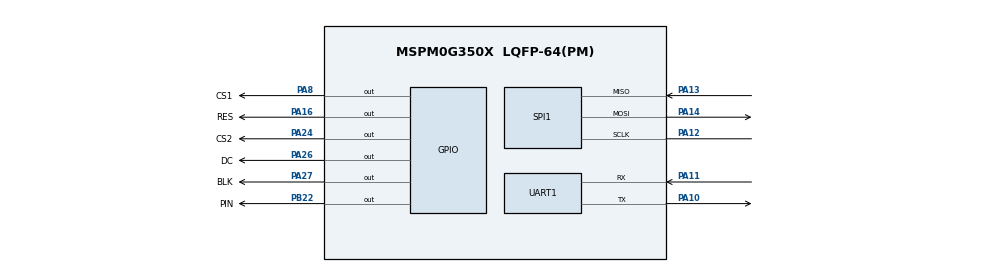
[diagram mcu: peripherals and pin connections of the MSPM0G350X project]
/**
 * @cliArgs --device "MSPM0G350X" --part "Default" --package "LQFP-64(PM)" --product "mspm0_sdk@2.02.00.05"
 * @versions {"tool":"1.21.0+3721"}
 */

/**
 * Import the modules used in this configuration.
 */
const GPIO   = scripting.addModule("/ti/driverlib/GPIO", {}, false);
const GPIO1  = GPIO.addInstance();
const GPIO2  = GPIO.addInstance();
const SPI    = scripting.addModule("/ti/driverlib/SPI", {}, false);
const SPI1   = SPI.addInstance();
const SYSCTL = scripting.addModule("/ti/driverlib/SYSCTL");
const UART   = scripting.addModule("/ti/driverlib/UART", {}, false);
const UART1  = UART.addInstance();

/**
 * Write custom configuration values to the imported modules.
 */
const divider9       = system.clockTree["UDIV"];
divider9.divideValue = 2;

const mux4       = system.clockTree["EXHFMUX"];
mux4.inputSelect = "EXHFMUX_XTAL";

const mux8       = system.clockTree["HSCLKMUX"];
mux8.inputSelect = "HSCLKMUX_SYSPLL2X";

const mux12       = system.clockTree["SYSPLLMUX"];
mux12.inputSelect = "zSYSPLLMUX_HFCLK";

const pinFunction4        = system.clockTree["HFXT"];
pinFunction4.inputFreq    = 40;
pinFunction4.enable       = true;
pinFunction4.HFCLKMonitor = true;
pinFunction4.HFXTStartup  = 20;

GPIO1.$name                          = "LED";
GPIO1.associatedPins[0].$name        = "PIN";
GPIO1.associatedPins[0].ioStructure  = "SD";
GPIO1.associatedPins[0].assignedPort = "PORTB";
GPIO1.associatedPins[0].assignedPin  = "22";
GPIO1.associatedPins[0].pin.$assign  = "PB22";

const Board = scripting.addModule("/ti/driverlib/Board", {}, false);

GPIO2.$name                          = "LCD";
GPIO2.port                           = "PORTA";
GPIO2.associatedPins.create(5);
GPIO2.associatedPins[0].$name        = "RES";
GPIO2.associatedPins[0].assignedPin  = "16";
GPIO2.associatedPins[0].ioStructure  = "SD";
GPIO2.associatedPins[0].pin.$assign  = "PA16";
GPIO2.associatedPins[1].$name        = "DC";
GPIO2.associatedPins[1].ioStructure  = "SD";
GPIO2.associatedPins[1].assignedPin  = "26";
GPIO2.associatedPins[1].initialValue = "SET";
GPIO2.associatedPins[1].pin.$assign  = "PA26";
GPIO2.associatedPins[2].$name        = "CS1";
GPIO2.associatedPins[2].assignedPin  = "8";
GPIO2.associatedPins[2].initialValue = "SET";
GPIO2.associatedPins[2].ioStructure  = "SD";
GPIO2.associatedPins[2].pin.$assign  = "PA8";
GPIO2.associatedPins[3].$name        = "BLK";
GPIO2.associatedPins[3].assignedPin  = "27";
GPIO2.associatedPins[3].initialValue = "SET";
GPIO2.associatedPins[3].ioStructure  = "SD";
GPIO2.associatedPins[3].pin.$assign  = "PA27";
GPIO2.associatedPins[4].$name        = "CS2";
GPIO2.associatedPins[4].ioStructure  = "SD";
GPIO2.associatedPins[4].assignedPin  = "24";
GPIO2.associatedPins[4].initialValue = "SET";
GPIO2.associatedPins[4].pin.$assign  = "PA24";

SPI1.frameFormat                        = "MOTO3";
SPI1.$name                              = "SPI_LCD";
SPI1.targetBitRate                      = 20000000;
SPI1.peripheral.$assign                 = "SPI0";
SPI1.peripheral.sclkPin.$assign         = "PA12";
SPI1.peripheral.mosiPin.$assign         = "PA14";
SPI1.peripheral.misoPin.$assign         = "PA13";
SPI1.sclkPinConfig.direction            = scripting.forceWrite("OUTPUT");
SPI1.sclkPinConfig.onlyInternalResistor = scripting.forceWrite(false);
SPI1.sclkPinConfig.passedPeripheralType = scripting.forceWrite("Digital");
SPI1.sclkPinConfig.$name                = "ti_driverlib_gpio_GPIOPinGeneric2";
SPI1.mosiPinConfig.direction            = scripting.forceWrite("OUTPUT");
SPI1.mosiPinConfig.hideOutputInversion  = scripting.forceWrite(false);
SPI1.mosiPinConfig.onlyInternalResistor = scripting.forceWrite(false);
SPI1.mosiPinConfig.passedPeripheralType = scripting.forceWrite("Digital");
SPI1.mosiPinConfig.$name                = "ti_driverlib_gpio_GPIOPinGeneric3";
SPI1.misoPinConfig.onlyInternalResistor = scripting.forceWrite(false);
SPI1.misoPinConfig.passedPeripheralType = scripting.forceWrite("Digital");
SPI1.misoPinConfig.$name                = "ti_driverlib_gpio_GPIOPinGeneric4";

SYSCTL.forceDefaultClkConfig = true;
SYSCTL.clockTreeEn           = true;
SYSCTL.validateClkStatus     = true;

UART1.$name                        = "UART_0";
UART1.targetBaudRate               = 115200;
UART1.peripheral.$assign           = "UART0";
UART1.peripheral.rxPin.$assign     = "PA11";
UART1.peripheral.txPin.$assign     = "PA10";
UART1.txPinConfig.$name            = "ti_driverlib_gpio_GPIOPinGeneric0";
UART1.txPinConfig.enableConfig     = true;
UART1.txPinConfig.internalResistor = "PULL_UP";
UART1.rxPinConfig.$name            = "ti_driverlib_gpio_GPIOPinGeneric1";
UART1.rxPinConfig.enableConfig     = true;
UART1.rxPinConfig.internalResistor = "PULL_UP";

/**
 * Pinmux solution for unlocked pins/peripherals. This ensures that minor changes to the automatic solver in a future
 * version of the tool will not impact the pinmux you originally saw.  These lines can be completely deleted in order to
 * re-solve from scratch.
 */
pinFunction4.peripheral.$suggestSolution           = "SYSCTL";
pinFunction4.peripheral.hfxInPin.$suggestSolution  = "PA5";
pinFunction4.peripheral.hfxOutPin.$suggestSolution = "PA6";
Board.peripheral.$suggestSolution                  = "DEBUGSS";
Board.peripheral.swclkPin.$suggestSolution         = "PA20";
Board.peripheral.swdioPin.$suggestSolution         = "PA19";
